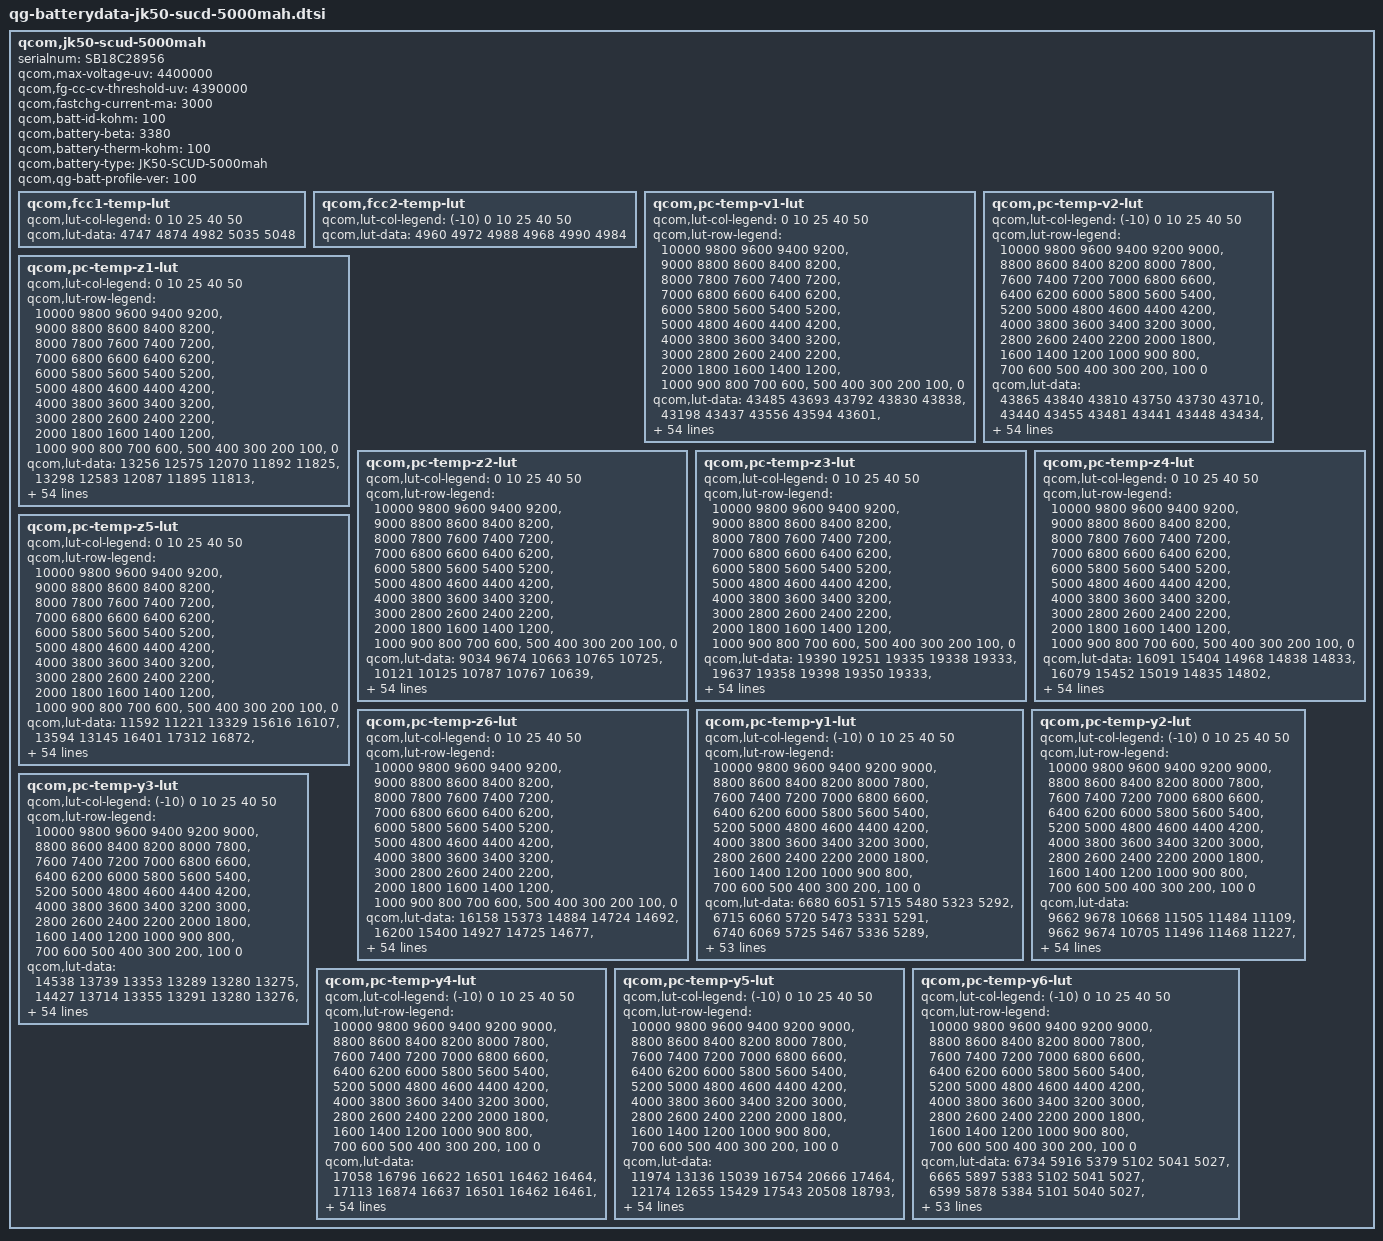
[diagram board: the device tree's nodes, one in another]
qcom,jk50-scud-5000mah {
    /* 3483956_Wingtech_JK50scud_4850mAh_averaged_MasterSlave_Jun21st2018 */
    serialnum = "SB18C28956";
    qcom,max-voltage-uv = <4400000>;
    qcom,fg-cc-cv-threshold-uv = <4390000>;
    qcom,fastchg-current-ma = <3000>;
    qcom,batt-id-kohm = <100>;
    qcom,battery-beta = <3380>;
    qcom,battery-therm-kohm = <100>;
    qcom,battery-type = "JK50-SCUD-5000mah";
    qcom,qg-batt-profile-ver = <100>;

	qcom,fcc1-temp-lut {
		qcom,lut-col-legend = <0 10 25 40 50>;
		qcom,lut-data = <4747 4874 4982 5035 5048>;
	};

	qcom,fcc2-temp-lut {
		qcom,lut-col-legend = <(-10) 0 10 25 40 50>;
		qcom,lut-data = <4960 4972 4988 4968 4990 4984>;
	};

	qcom,pc-temp-v1-lut {
		qcom,lut-col-legend = <0 10 25 40 50>;
		qcom,lut-row-legend = <10000 9800 9600 9400 9200>,
			<9000 8800 8600 8400 8200>,
			<8000 7800 7600 7400 7200>,
			<7000 6800 6600 6400 6200>,
			<6000 5800 5600 5400 5200>,
			<5000 4800 4600 4400 4200>,
			<4000 3800 3600 3400 3200>,
			<3000 2800 2600 2400 2200>,
			<2000 1800 1600 1400 1200>,
			<1000 900 800 700 600>,
			<500 400 300 200 100>,
			<0>;
		qcom,lut-data = <43485 43693 43792 43830 43838>,
			<43198 43437 43556 43594 43601>,
			<42941 43171 43314 43362 43374>,
			<42706 42915 43070 43125 43142>,
			<42480 42676 42828 42889 42908>,
			<42257 42445 42590 42654 42674>,
			<42040 42217 42355 42419 42442>,
			<41828 41995 42123 42186 42210>,
			<41619 41778 41894 41956 41976>,
			<41419 41563 41670 41727 41745>,
			<41248 41358 41446 41500 41519>,
			<41090 41181 41236 41277 41299>,
			<40890 41019 41054 41063 41083>,
			<40593 40817 40882 40860 40872>,
			<40293 40525 40664 40658 40666>,
			<40084 40244 40382 40451 40466>,
			<39918 40056 40144 40251 40274>,
			<39773 39906 39995 40074 40095>,
			<39644 39769 39870 39913 39928>,
			<39525 39647 39730 39751 39761>,
			<39404 39523 39582 39592 39598>,
			<39286 39378 39400 39419 39425>,
			<39169 39219 39126 39185 39203>,
			<39052 39041 38864 38929 38955>,
			<38938 38819 38730 38769 38788>,
			<38825 38632 38640 38668 38682>,
			<38710 38529 38558 38577 38586>,
			<38607 38453 38481 38480 38479>,
			<38518 38395 38409 38387 38378>,
			<38440 38349 38339 38305 38291>,
			<38378 38310 38275 38232 38216>,
			<38326 38271 38217 38165 38148>,
			<38286 38235 38167 38106 38090>,
			<38262 38202 38120 38051 38033>,
			<38246 38174 38076 37999 37974>,
			<38221 38142 38034 37950 37914>,
			<38181 38106 37992 37900 37855>,
			<38132 38065 37951 37851 37800>,
			<38072 38006 37897 37790 37734>,
			<37999 37917 37811 37705 37643>,
			<37909 37816 37705 37599 37532>,
			<37788 37716 37592 37486 37416>,
			<37650 37601 37464 37358 37289>,
			<37497 37444 37312 37209 37136>,
			<37348 37291 37168 37070 37000>,
			<37240 37182 37075 36978 36920>,
			<37202 37149 37044 36952 36893>,
			<37173 37121 37026 36934 36873>,
			<37145 37096 37009 36914 36852>,
			<37095 37047 36959 36849 36783>,
			<36879 36821 36723 36586 36506>,
			<36445 36388 36301 36146 36069>,
			<35877 35817 35735 35571 35498>,
			<35105 35037 34962 34786 34718>,
			<33888 33820 33779 33569 33519>,
			<30000 30000 30000 30000 30000>;
	};

	qcom,pc-temp-v2-lut {
		qcom,lut-col-legend = <(-10) 0 10 25 40 50>;
		qcom,lut-row-legend = <10000 9800 9600 9400 9200 9000>,
			<8800 8600 8400 8200 8000 7800>,
			<7600 7400 7200 7000 6800 6600>,
			<6400 6200 6000 5800 5600 5400>,
			<5200 5000 4800 4600 4400 4200>,
			<4000 3800 3600 3400 3200 3000>,
			<2800 2600 2400 2200 2000 1800>,
			<1600 1400 1200 1000 900 800>,
			<700 600 500 400 300 200>,
			<100 0>;
		qcom,lut-data = <43865 43840 43810 43750 43730 43710>,
			<43440 43455 43481 43441 43448 43434>,
			<43056 43105 43175 43154 43181 43170>,
			<42718 42793 42898 42891 42928 42920>,
			<42417 42514 42647 42650 42688 42684>,
			<42139 42253 42401 42415 42452 42450>,
			<41873 42009 42155 42180 42217 42216>,
			<41631 41775 41916 41949 41984 41983>,
			<41426 41535 41691 41722 41755 41754>,
			<41247 41293 41476 41499 41529 41528>,
			<41091 41122 41269 41281 41307 41305>,
			<40972 41031 41077 41068 41087 41086>,
			<40831 40928 40879 40860 40873 40872>,
			<40486 40636 40652 40658 40669 40665>,
			<39938 40158 40408 40458 40471 40464>,
			<39599 39838 40176 40254 40279 40271>,
			<39423 39648 39954 40039 40088 40087>,
			<39272 39474 39743 39845 39907 39909>,
			<39099 39282 39547 39699 39743 39744>,
			<38928 39091 39359 39567 39581 39579>,
			<38774 38913 39166 39384 39384 39386>,
			<38630 38743 38966 39130 39150 39158>,
			<38507 38592 38790 38900 38938 38949>,
			<38406 38457 38639 38728 38761 38770>,
			<38321 38340 38505 38583 38607 38613>,
			<38243 38251 38384 38459 38482 38485>,
			<38175 38180 38274 38353 38376 38377>,
			<38110 38117 38177 38258 38279 38278>,
			<38051 38062 38090 38173 38189 38187>,
			<37994 38012 38015 38096 38106 38104>,
			<37936 37964 37955 38022 38034 38030>,
			<37878 37918 37904 37951 37968 37962>,
			<37818 37872 37855 37886 37904 37897>,
			<37756 37824 37808 37829 37844 37836>,
			<37693 37774 37762 37775 37779 37769>,
			<37630 37721 37717 37721 37695 37673>,
			<37565 37664 37671 37668 37603 37562>,
			<37500 37601 37612 37607 37519 37466>,
			<37434 37533 37539 37537 37440 37380>,
			<37367 37455 37458 37461 37361 37296>,
			<37299 37356 37367 37379 37282 37217>,
			<37231 37255 37267 37284 37193 37130>,
			<37162 37170 37156 37169 37078 37020>,
			<37084 37093 37072 37041 36951 36891>,
			<36994 37006 36992 36929 36836 36782>,
			<36864 36886 36881 36864 36802 36746>,
			<36779 36810 36815 36848 36785 36734>,
			<36679 36723 36744 36828 36768 36717>,
			<36567 36642 36695 36792 36735 36686>,
			<36425 36579 36623 36724 36630 36573>,
			<36219 36418 36431 36480 36299 36236>,
			<35863 36015 35969 36015 35791 35737>,
			<35288 35396 35329 35393 35131 35083>,
			<34412 34531 34446 34553 34212 34177>,
			<32898 33107 33075 33275 32827 32842>,
			<30006 28192 27750 28954 27842 28553>;
	};

	qcom,pc-temp-z1-lut {
		qcom,lut-col-legend = <0 10 25 40 50>;
		qcom,lut-row-legend = <10000 9800 9600 9400 9200>,
			<9000 8800 8600 8400 8200>,
			<8000 7800 7600 7400 7200>,
			<7000 6800 6600 6400 6200>,
			<6000 5800 5600 5400 5200>,
			<5000 4800 4600 4400 4200>,
			<4000 3800 3600 3400 3200>,
			<3000 2800 2600 2400 2200>,
			<2000 1800 1600 1400 1200>,
			<1000 900 800 700 600>,
			<500 400 300 200 100>,
			<0>;
		qcom,lut-data = <13256 12575 12070 11892 11825>,
			<13298 12583 12087 11895 11813>,
			<13303 12582 12089 11892 11810>,
			<13285 12583 12079 11881 11802>,
			<13269 12584 12073 11871 11796>,
			<13266 12581 12070 11866 11791>,
			<13266 12574 12068 11863 11788>,
			<13260 12562 12065 11859 11787>,
			<13247 12558 12061 11856 11786>,
			<13241 12557 12059 11854 11786>,
			<13248 12557 12059 11855 11787>,
			<13254 12557 12062 11855 11789>,
			<13245 12556 12061 11856 11789>,
			<13200 12549 12057 11857 11789>,
			<13156 12527 12053 11857 11789>,
			<13135 12508 12048 11855 11789>,
			<13117 12504 12046 11854 11790>,
			<13111 12503 12046 11854 11791>,
			<13120 12505 12046 11856 11792>,
			<13132 12516 12048 11858 11794>,
			<13129 12527 12056 11859 11795>,
			<13111 12532 12061 11860 11797>,
			<13102 12536 12061 11862 11798>,
			<13120 12541 12062 11866 11799>,
			<13148 12546 12064 11868 11800>,
			<13157 12550 12068 11871 11804>,
			<13159 12551 12071 11874 11808>,
			<13159 12552 12074 11876 11810>,
			<13159 12552 12077 11879 11813>,
			<13161 12551 12080 11884 11816>,
			<13162 12551 12083 11890 11820>,
			<13162 12556 12085 11894 11824>,
			<13164 12564 12088 11897 11828>,
			<13171 12570 12091 11900 11832>,
			<13181 12579 12097 11906 11837>,
			<13184 12586 12103 11913 11843>,
			<13194 12593 12106 11916 11847>,
			<13204 12604 12107 11917 11851>,
			<13215 12610 12110 11918 11854>,
			<13239 12618 12121 11924 11857>,
			<13247 12625 12132 11931 11859>,
			<13254 12628 12131 11934 11864>,
			<13261 12630 12126 11937 11870>,
			<13261 12637 12133 11941 11872>,
			<13269 12639 12145 11944 11874>,
			<13238 12641 12141 11944 11877>,
			<13239 12638 12143 11945 11876>,
			<13270 12627 12144 11948 11878>,
			<13263 12648 12140 11949 11882>,
			<13252 12629 12219 11953 11884>,
			<13303 12653 12156 11964 11890>,
			<13291 12665 12160 11971 11898>,
			<13307 12695 12173 11979 11909>,
			<13344 12730 12198 11997 11922>,
			<13344 12730 12198 11997 11922>,
			<13344 12730 12198 11997 11922>;
	};

	qcom,pc-temp-z2-lut {
		qcom,lut-col-legend = <0 10 25 40 50>;
		qcom,lut-row-legend = <10000 9800 9600 9400 9200>,
			<9000 8800 8600 8400 8200>,
			<8000 7800 7600 7400 7200>,
			<7000 6800 6600 6400 6200>,
			<6000 5800 5600 5400 5200>,
			<5000 4800 4600 4400 4200>,
			<4000 3800 3600 3400 3200>,
			<3000 2800 2600 2400 2200>,
			<2000 1800 1600 1400 1200>,
			<1000 900 800 700 600>,
			<500 400 300 200 100>,
			<0>;
		qcom,lut-data = <9034 9674 10663 10765 10725>,
			<10121 10125 10787 10767 10639>,
			<10373 10493 10853 10891 10675>,
			<10398 10604 10859 10864 10766>,
			<10415 10592 10847 10827 10825>,
			<10436 10572 10820 10814 10805>,
			<10455 10555 10791 10805 10719>,
			<10461 10536 10771 10789 10675>,
			<10462 10520 10753 10740 10676>,
			<10459 10505 10738 10706 10680>,
			<10382 10497 10724 10712 10679>,
			<10143 10516 10716 10721 10676>,
			<10019 10567 10739 10719 10665>,
			<10125 10585 10786 10705 10632>,
			<10283 10567 10810 10698 10615>,
			<10366 10550 10821 10725 10645>,
			<10463 10562 10823 10757 10679>,
			<10497 10602 10815 10756 10655>,
			<10454 10644 10811 10744 10585>,
			<10415 10696 10830 10743 10560>,
			<10422 10736 10877 10794 10639>,
			<10428 10747 10896 10840 10718>,
			<10433 10754 10889 10826 10697>,
			<10437 10754 10876 10791 10642>,
			<10441 10746 10859 10769 10630>,
			<10449 10739 10836 10758 10653>,
			<10462 10751 10830 10763 10692>,
			<10477 10776 10851 10879 10813>,
			<10494 10783 10876 11031 10957>,
			<10515 10777 10892 11023 10939>,
			<10540 10773 10911 10918 10778>,
			<10573 10779 10915 10832 10644>,
			<10595 10796 10905 10770 10548>,
			<10345 10812 10898 10734 10491>,
			<9819 10830 10903 10754 10505>,
			<9652 10849 10914 10811 10547>,
			<9741 10870 10928 10866 10586>,
			<9842 10892 10951 10927 10643>,
			<9891 10918 10978 10970 10701>,
			<9936 10952 11019 10998 10786>,
			<9949 10971 11056 11021 10873>,
			<9862 10848 11068 11028 10866>,
			<9797 10671 11074 11030 10806>,
			<9816 10611 11078 11038 10874>,
			<9724 12174 11129 11035 10940>,
			<9649 14416 11230 10993 10790>,
			<9693 13140 11233 10967 10802>,
			<9703 13467 11241 10974 10813>,
			<9679 14092 11296 11005 10871>,
			<9664 14667 11387 11156 10993>,
			<9590 13142 11358 11016 10724>,
			<9567 12520 11366 10836 10551>,
			<9502 11311 11285 10745 10455>,
			<9427 11330 11100 10671 10428>,
			<9427 11330 11100 10671 10428>,
			<9427 11330 11100 10671 10428>;
	};

	qcom,pc-temp-z3-lut {
		qcom,lut-col-legend = <0 10 25 40 50>;
		qcom,lut-row-legend = <10000 9800 9600 9400 9200>,
			<9000 8800 8600 8400 8200>,
			<8000 7800 7600 7400 7200>,
			<7000 6800 6600 6400 6200>,
			<6000 5800 5600 5400 5200>,
			<5000 4800 4600 4400 4200>,
			<4000 3800 3600 3400 3200>,
			<3000 2800 2600 2400 2200>,
			<2000 1800 1600 1400 1200>,
			<1000 900 800 700 600>,
			<500 400 300 200 100>,
			<0>;
		qcom,lut-data = <19390 19251 19335 19338 19333>,
			<19637 19358 19398 19350 19333>,
			<19703 19506 19427 19372 19354>,
			<19715 19572 19438 19383 19368>,
			<19719 19577 19443 19388 19376>,
			<19712 19579 19446 19391 19378>,
			<19700 19578 19447 19393 19379>,
			<19692 19574 19446 19393 19381>,
			<19684 19572 19442 19392 19385>,
			<19677 19570 19440 19391 19388>,
			<19633 19566 19439 19389 19385>,
			<19508 19547 19437 19387 19378>,
			<19451 19509 19427 19382 19373>,
			<19571 19499 19411 19376 19369>,
			<19717 19523 19409 19372 19366>,
			<19737 19545 19424 19373 19364>,
			<19722 19539 19433 19375 19363>,
			<19702 19517 19421 19373 19359>,
			<19654 19499 19404 19365 19351>,
			<19609 19483 19400 19361 19347>,
			<19603 19473 19399 19359 19346>,
			<19602 19480 19399 19358 19345>,
			<19601 19498 19408 19357 19343>,
			<19614 19511 19417 19357 19340>,
			<19632 19520 19414 19354 19336>,
			<19641 19526 19404 19343 19332>,
			<19649 19526 19400 19337 19329>,
			<19653 19526 19400 19353 19354>,
			<19651 19525 19400 19377 19391>,
			<19646 19521 19404 19384 19395>,
			<19641 19515 19412 19388 19388>,
			<19630 19510 19416 19389 19380>,
			<19613 19504 19417 19385 19372>,
			<19513 19499 19418 19380 19363>,
			<19331 19492 19417 19374 19356>,
			<19268 19486 19415 19367 19351>,
			<19266 19482 19412 19362 19346>,
			<19265 19479 19406 19358 19341>,
			<19264 19479 19403 19356 19338>,
			<19263 19479 19401 19354 19339>,
			<19263 19477 19400 19353 19340>,
			<19264 19378 19397 19352 19341>,
			<19265 19262 19394 19351 19342>,
			<19264 19261 19391 19351 19347>,
			<19265 19259 19386 19348 19350>,
			<19267 19257 19370 19338 19334>,
			<19266 19257 19368 19332 19325>,
			<19265 19257 19360 19326 19320>,
			<19266 19257 19337 19324 19314>,
			<19266 19257 19335 19319 19309>,
			<19268 19257 19353 19329 19339>,
			<19268 19257 19341 19340 19342>,
			<19270 19259 19347 19339 19343>,
			<19273 19259 19363 19343 19341>,
			<19273 19259 19363 19343 19341>,
			<19273 19259 19363 19343 19341>;
	};

	qcom,pc-temp-z4-lut {
		qcom,lut-col-legend = <0 10 25 40 50>;
		qcom,lut-row-legend = <10000 9800 9600 9400 9200>,
			<9000 8800 8600 8400 8200>,
			<8000 7800 7600 7400 7200>,
			<7000 6800 6600 6400 6200>,
			<6000 5800 5600 5400 5200>,
			<5000 4800 4600 4400 4200>,
			<4000 3800 3600 3400 3200>,
			<3000 2800 2600 2400 2200>,
			<2000 1800 1600 1400 1200>,
			<1000 900 800 700 600>,
			<500 400 300 200 100>,
			<0>;
		qcom,lut-data = <16091 15404 14968 14838 14833>,
			<16079 15452 15019 14835 14802>,
			<15985 15351 15046 14880 14833>,
			<15782 15244 14974 14860 14826>,
			<15595 15137 14909 14827 14805>,
			<15471 15041 14864 14802 14787>,
			<15368 14973 14826 14780 14769>,
			<15285 14919 14797 14760 14752>,
			<15211 14876 14774 14744 14735>,
			<15154 14841 14755 14729 14720>,
			<15148 14817 14739 14716 14709>,
			<15210 14805 14725 14705 14702>,
			<15229 14798 14712 14697 14696>,
			<15106 14787 14701 14692 14692>,
			<14952 14766 14700 14688 14688>,
			<14896 14748 14706 14683 14684>,
			<14859 14740 14709 14678 14679>,
			<14848 14734 14697 14672 14675>,
			<14863 14730 14679 14666 14671>,
			<14878 14725 14674 14664 14670>,
			<14869 14721 14672 14666 14672>,
			<14848 14713 14675 14671 14676>,
			<14824 14704 14741 14714 14712>,
			<14793 14707 14812 14791 14786>,
			<14764 14758 14816 14808 14805>,
			<14754 14801 14810 14804 14797>,
			<14749 14799 14802 14796 14785>,
			<14747 14790 14786 14769 14747>,
			<14747 14779 14768 14732 14698>,
			<14748 14764 14750 14711 14685>,
			<14748 14748 14732 14695 14681>,
			<14746 14736 14717 14685 14677>,
			<14744 14725 14705 14678 14672>,
			<14830 14715 14695 14674 14669>,
			<15013 14707 14690 14673 14669>,
			<15074 14701 14685 14673 14670>,
			<15063 14694 14683 14673 14670>,
			<15048 14688 14681 14672 14670>,
			<15036 14686 14681 14672 14669>,
			<15024 14685 14685 14678 14675>,
			<15015 14685 14690 14686 14684>,
			<15010 14783 14689 14686 14684>,
			<15003 14899 14683 14680 14677>,
			<14984 14894 14681 14680 14675>,
			<14914 14859 14674 14678 14670>,
			<14880 14828 14657 14660 14655>,
			<14876 14821 14651 14658 14656>,
			<14872 14816 14649 14650 14648>,
			<14865 14809 14663 14636 14635>,
			<14862 14805 14661 14639 14636>,
			<14866 14814 14661 14656 14640>,
			<14885 14826 14683 14656 14649>,
			<14899 14834 14681 14661 14653>,
			<14915 14843 14669 14661 14659>,
			<14915 14843 14669 14661 14659>,
			<14915 14843 14669 14661 14659>;
	};

	qcom,pc-temp-z5-lut {
		qcom,lut-col-legend = <0 10 25 40 50>;
		qcom,lut-row-legend = <10000 9800 9600 9400 9200>,
			<9000 8800 8600 8400 8200>,
			<8000 7800 7600 7400 7200>,
			<7000 6800 6600 6400 6200>,
			<6000 5800 5600 5400 5200>,
			<5000 4800 4600 4400 4200>,
			<4000 3800 3600 3400 3200>,
			<3000 2800 2600 2400 2200>,
			<2000 1800 1600 1400 1200>,
			<1000 900 800 700 600>,
			<500 400 300 200 100>,
			<0>;
		qcom,lut-data = <11592 11221 13329 15616 16107>,
			<13594 13145 16401 17312 16872>,
			<14386 15417 17404 18541 18534>,
			<14698 16893 18322 19395 19833>,
			<14917 17574 19268 20084 20945>,
			<15146 18085 20133 20644 21530>,
			<15362 18663 20811 21187 21844>,
			<15557 19329 21309 21742 22423>,
			<15748 20037 21820 22260 24431>,
			<15905 21018 22482 22866 26263>,
			<15536 21689 23650 24032 26593>,
			<14168 20823 24411 25365 26737>,
			<13740 18611 24050 25571 26956>,
			<16828 18297 23026 25268 27315>,
			<20591 24197 24110 25157 27858>,
			<21563 29699 31048 27952 29592>,
			<21394 28707 35189 31420 31578>,
			<20723 25436 31760 31686 31482>,
			<18683 23541 27405 31430 30193>,
			<16824 22588 27599 31398 29705>,
			<16790 22116 30911 32724 31505>,
			<17375 26031 35255 34041 33332>,
			<18347 36592 42361 32981 31504>,
			<20898 44631 47955 29891 26404>,
			<24806 52511 44209 26186 22364>,
			<29065 57236 33025 20869 18762>,
			<35368 55539 27300 18211 16998>,
			<40043 51052 25306 19945 22460>,
			<41587 47076 24425 23082 30763>,
			<42366 43365 25322 25961 32866>,
			<41522 40393 27658 29156 33442>,
			<38663 38615 30110 32022 33359>,
			<34464 37264 32978 34807 32457>,
			<26268 36139 36030 36733 31650>,
			<15112 34771 39821 37314 32012>,
			<11627 33709 43021 37679 32989>,
			<11625 33915 42979 37606 33140>,
			<11624 35159 41255 36524 31942>,
			<11633 36115 40050 34970 30475>,
			<11662 38579 39139 32696 29165>,
			<11698 40240 37992 30075 27967>,
			<11757 27430 35768 28159 27300>,
			<11813 12139 32740 26718 26836>,
			<11855 12099 32292 26532 29541>,
			<12244 12283 32656 26209 32053>,
			<12386 12382 30401 24859 24994>,
			<12358 12284 30268 22733 21105>,
			<12339 12270 27048 21691 21051>,
			<12364 12268 19592 23347 21714>,
			<12348 12301 19553 21268 19855>,
			<12461 12354 22713 20147 27204>,
			<12326 12232 18793 20761 23710>,
			<12198 12152 18647 19387 21460>,
			<12044 12020 20356 18837 18803>,
			<12044 12020 20356 18837 18803>,
			<12044 12020 20356 18837 18803>;
	};

	qcom,pc-temp-z6-lut {
		qcom,lut-col-legend = <0 10 25 40 50>;
		qcom,lut-row-legend = <10000 9800 9600 9400 9200>,
			<9000 8800 8600 8400 8200>,
			<8000 7800 7600 7400 7200>,
			<7000 6800 6600 6400 6200>,
			<6000 5800 5600 5400 5200>,
			<5000 4800 4600 4400 4200>,
			<4000 3800 3600 3400 3200>,
			<3000 2800 2600 2400 2200>,
			<2000 1800 1600 1400 1200>,
			<1000 900 800 700 600>,
			<500 400 300 200 100>,
			<0>;
		qcom,lut-data = <16158 15373 14884 14724 14692>,
			<16200 15400 14927 14725 14677>,
			<16179 15390 14943 14752 14700>,
			<16050 15372 14910 14746 14701>,
			<15912 15309 14878 14733 14697>,
			<15821 15235 14853 14723 14691>,
			<15744 15186 14832 14712 14683>,
			<15680 15147 14813 14703 14676>,
			<15629 15115 14798 14694 14671>,
			<15582 15091 14786 14687 14666>,
			<15533 15068 14777 14680 14660>,
			<15483 15039 14768 14673 14653>,
			<15451 15009 14755 14667 14648>,
			<15434 14991 14740 14661 14644>,
			<15418 14983 14738 14657 14640>,
			<15396 14976 14745 14655 14637>,
			<15367 14966 14749 14653 14634>,
			<15341 14955 14739 14649 14630>,
			<15320 14945 14724 14643 14624>,
			<15302 14938 14721 14640 14622>,
			<15288 14933 14721 14641 14623>,
			<15277 14935 14724 14642 14624>,
			<15270 14943 14757 14660 14638>,
			<15266 14954 14793 14693 14668>,
			<15264 14983 14795 14700 14676>,
			<15264 15005 14789 14694 14670>,
			<15271 15005 14784 14688 14665>,
			<15276 15003 14778 14685 14663>,
			<15278 15000 14773 14683 14662>,
			<15278 14993 14769 14680 14659>,
			<15277 14986 14766 14676 14654>,
			<15272 14979 14764 14672 14649>,
			<15266 14974 14761 14668 14643>,
			<15257 14969 14759 14665 14638>,
			<15248 14965 14757 14662 14635>,
			<15244 14962 14756 14660 14633>,
			<15243 14962 14755 14658 14631>,
			<15243 14962 14754 14656 14628>,
			<15243 14962 14753 14655 14627>,
			<15244 14967 14757 14658 14631>,
			<15246 14970 14761 14662 14636>,
			<15252 14968 14761 14662 14636>,
			<15256 14965 14760 14661 14635>,
			<15256 14968 14761 14661 14637>,
			<15241 14963 14759 14660 14638>,
			<15229 14953 14747 14648 14624>,
			<15228 14951 14743 14645 14620>,
			<15226 14950 14739 14638 14613>,
			<15223 14949 14735 14632 14604>,
			<15228 14951 14736 14632 14603>,
			<15239 14960 14748 14646 14622>,
			<15254 14971 14756 14654 14631>,
			<15273 14985 14763 14660 14636>,
			<15301 15004 14773 14666 14641>,
			<15301 15004 14773 14666 14641>,
			<15301 15004 14773 14666 14641>;
	};

	qcom,pc-temp-y1-lut {
		qcom,lut-col-legend = <(-10) 0 10 25 40 50>;
		qcom,lut-row-legend = <10000 9800 9600 9400 9200 9000>,
			<8800 8600 8400 8200 8000 7800>,
			<7600 7400 7200 7000 6800 6600>,
			<6400 6200 6000 5800 5600 5400>,
			<5200 5000 4800 4600 4400 4200>,
			<4000 3800 3600 3400 3200 3000>,
			<2800 2600 2400 2200 2000 1800>,
			<1600 1400 1200 1000 900 800>,
			<700 600 500 400 300 200>,
			<100 0>;
		qcom,lut-data = <6680 6051 5715 5480 5323 5292>,
			<6715 6060 5720 5473 5331 5291>,
			<6740 6069 5725 5467 5336 5289>,
			<6755 6078 5730 5462 5339 5288>,
			<6762 6083 5734 5459 5340 5287>,
			<6764 6085 5736 5457 5340 5286>,
			<6752 6079 5737 5457 5337 5285>,
			<6740 6071 5737 5458 5334 5284>,
			<6740 6068 5733 5458 5332 5282>,
			<6747 6066 5728 5456 5331 5280>,
			<6749 6068 5727 5455 5330 5279>,
			<6756 6075 5729 5455 5328 5278>,
			<6764 6084 5732 5455 5326 5277>,
			<6759 6089 5734 5455 5325 5277>,
			<6747 6093 5739 5454 5323 5277>,
			<6744 6097 5740 5455 5323 5277>,
			<6752 6103 5740 5460 5325 5276>,
			<6761 6107 5740 5464 5327 5276>,
			<6767 6101 5741 5464 5328 5277>,
			<6771 6090 5745 5464 5328 5278>,
			<6766 6088 5747 5464 5329 5279>,
			<6748 6089 5748 5463 5329 5279>,
			<6734 6092 5749 5463 5329 5279>,
			<6736 6103 5750 5466 5332 5281>,
			<6743 6116 5751 5469 5335 5283>,
			<6739 6116 5751 5469 5337 5285>,
			<6724 6109 5749 5470 5339 5287>,
			<6715 6103 5748 5470 5340 5289>,
			<6726 6099 5749 5475 5342 5290>,
			<6742 6097 5749 5482 5343 5291>,
			<6740 6099 5747 5484 5346 5293>,
			<6728 6103 5744 5485 5348 5297>,
			<6723 6104 5744 5485 5350 5301>,
			<6724 6099 5748 5485 5351 5304>,
			<6726 6092 5752 5486 5352 5306>,
			<6730 6091 5750 5486 5356 5308>,
			<6737 6094 5747 5487 5361 5309>,
			<6743 6096 5748 5487 5362 5311>,
			<6749 6098 5753 5486 5363 5314>,
			<6751 6098 5755 5486 5364 5316>,
			<6735 6099 5752 5487 5366 5317>,
			<6722 6096 5750 5490 5367 5317>,
			<6742 6100 5756 5491 5371 5320>,
			<6732 6112 5754 5490 5374 5322>,
			<6779 6116 5763 5494 5377 5326>,
			<6778 6122 5769 5493 5381 5330>,
			<6791 6139 5762 5502 5380 5331>,
			<6772 6145 5767 5496 5381 5328>,
			<6768 6130 5762 5498 5377 5328>,
			<6793 6146 5768 5504 5377 5331>,
			<6797 6155 5777 5506 5381 5332>,
			<6806 6155 5782 5515 5391 5337>,
			<6831 6195 5801 5524 5399 5345>,
			<6887 6221 5824 5538 5408 5353>,
			<6887 6221 5824 5538 5408 5353>,
			<6887 6221 5824 5538 5408 5353>;
	};

	qcom,pc-temp-y2-lut {
		qcom,lut-col-legend = <(-10) 0 10 25 40 50>;
		qcom,lut-row-legend = <10000 9800 9600 9400 9200 9000>,
			<8800 8600 8400 8200 8000 7800>,
			<7600 7400 7200 7000 6800 6600>,
			<6400 6200 6000 5800 5600 5400>,
			<5200 5000 4800 4600 4400 4200>,
			<4000 3800 3600 3400 3200 3000>,
			<2800 2600 2400 2200 2000 1800>,
			<1600 1400 1200 1000 900 800>,
			<700 600 500 400 300 200>,
			<100 0>;
		qcom,lut-data = <9662 9678 10668 11505 11484 11109>,
			<9662 9674 10705 11496 11468 11227>,
			<9663 9674 10752 11483 11447 11302>,
			<9663 9676 10799 11467 11424 11341>,
			<9664 9679 10834 11448 11401 11351>,
			<9664 9684 10846 11427 11379 11338>,
			<9665 9693 10843 11403 11331 11276>,
			<9665 9700 10837 11377 11284 11208>,
			<9665 9700 10828 11350 11289 11197>,
			<9665 9697 10817 11320 11328 11199>,
			<9665 9695 10818 11295 11338 11191>,
			<9665 9699 10884 11272 11320 11139>,
			<9666 9703 10974 11259 11301 11094>,
			<9665 9701 11050 11265 11290 11093>,
			<9665 9694 11126 11290 11283 11095>,
			<9664 9689 11180 11325 11294 11112>,
			<9664 9686 11227 11393 11342 11217>,
			<9664 9683 11253 11471 11405 11317>,
			<9664 9681 11258 11561 11491 11360>,
			<9664 9680 11261 11648 11580 11393>,
			<9664 9680 11269 11656 11613 11411>,
			<9664 9679 11290 11610 11626 11402>,
			<9664 9678 11309 11582 11626 11391>,
			<9664 9678 11324 11631 11604 11381>,
			<9664 9677 11339 11700 11584 11381>,
			<9663 9676 11354 11715 11603 11406>,
			<9663 9674 11369 11716 11656 11442>,
			<9663 9673 11326 11719 11695 11481>,
			<9663 9671 10675 11735 11746 11531>,
			<9663 9670 10071 11754 11793 11568>,
			<9663 9669 10228 11762 11813 11580>,
			<9662 9668 10561 11759 11826 11587>,
			<9662 9666 10544 11753 11832 11609>,
			<9662 9665 10126 11752 11839 11687>,
			<9662 9664 9847 11753 11840 11741>,
			<9662 9664 9799 11741 11827 11698>,
			<9662 9663 9766 11713 11801 11631>,
			<9662 9662 9742 11681 11758 11619>,
			<9662 9662 9723 11649 11681 11596>,
			<9661 9661 9711 11611 11635 11568>,
			<9661 9661 9703 11557 11645 11535>,
			<9661 9661 9696 11504 11641 11508>,
			<9660 9660 9689 11465 11561 11472>,
			<9660 9660 9682 11410 11630 11424>,
			<9660 9660 9681 11385 11567 11362>,
			<9660 9659 9675 10943 11475 11238>,
			<9660 9659 9673 11230 11424 11199>,
			<9659 9659 9673 11233 11444 11209>,
			<9659 9659 9674 11207 11431 11280>,
			<9659 9659 9676 11227 11439 11293>,
			<9658 9659 9677 11168 11333 11148>,
			<9658 9658 9672 11012 11275 11064>,
			<9657 9658 9664 10895 11174 11004>,
			<9655 9657 9660 10739 11005 10825>,
			<9655 9657 9660 10739 11005 10825>,
			<9655 9657 9660 10739 11005 10825>;
	};

	qcom,pc-temp-y3-lut {
		qcom,lut-col-legend = <(-10) 0 10 25 40 50>;
		qcom,lut-row-legend = <10000 9800 9600 9400 9200 9000>,
			<8800 8600 8400 8200 8000 7800>,
			<7600 7400 7200 7000 6800 6600>,
			<6400 6200 6000 5800 5600 5400>,
			<5200 5000 4800 4600 4400 4200>,
			<4000 3800 3600 3400 3200 3000>,
			<2800 2600 2400 2200 2000 1800>,
			<1600 1400 1200 1000 900 800>,
			<700 600 500 400 300 200>,
			<100 0>;
		qcom,lut-data = <14538 13739 13353 13289 13280 13275>,
			<14427 13714 13355 13291 13280 13276>,
			<14319 13683 13358 13292 13280 13277>,
			<14220 13652 13362 13294 13280 13277>,
			<14133 13627 13365 13295 13280 13278>,
			<14065 13613 13366 13296 13280 13279>,
			<14017 13609 13367 13296 13281 13279>,
			<13973 13605 13368 13297 13281 13280>,
			<13895 13582 13371 13297 13281 13280>,
			<13789 13527 13376 13298 13283 13281>,
			<13752 13502 13378 13298 13283 13281>,
			<13768 13498 13377 13299 13283 13281>,
			<13785 13495 13375 13300 13283 13281>,
			<13766 13490 13368 13303 13285 13281>,
			<13718 13484 13355 13307 13288 13282>,
			<13697 13477 13350 13308 13289 13283>,
			<13690 13463 13349 13305 13289 13285>,
			<13688 13447 13348 13302 13289 13287>,
			<13689 13429 13344 13303 13290 13287>,
			<13693 13413 13338 13304 13290 13288>,
			<13694 13407 13332 13304 13290 13287>,
			<13696 13405 13327 13299 13286 13283>,
			<13698 13405 13323 13294 13283 13280>,
			<13705 13404 13320 13290 13281 13278>,
			<13718 13404 13318 13288 13279 13277>,
			<13730 13407 13316 13287 13279 13277>,
			<13743 13417 13313 13286 13279 13277>,
			<13759 13429 13307 13286 13279 13277>,
			<13782 13443 13283 13288 13278 13277>,
			<13809 13462 13264 13290 13278 13276>,
			<13838 13484 13271 13290 13278 13276>,
			<13868 13511 13285 13289 13278 13276>,
			<13899 13539 13289 13289 13279 13276>,
			<13930 13567 13297 13289 13280 13277>,
			<13962 13599 13305 13290 13280 13278>,
			<13998 13636 13313 13290 13279 13277>,
			<14037 13676 13320 13290 13278 13275>,
			<14078 13721 13322 13290 13278 13275>,
			<14121 13770 13323 13291 13278 13276>,
			<14164 13821 13324 13291 13278 13276>,
			<14209 13869 13334 13291 13279 13277>,
			<14256 13920 13348 13292 13279 13278>,
			<14316 13979 13359 13293 13279 13279>,
			<14369 14049 13386 13293 13279 13277>,
			<14318 14021 13389 13292 13275 13274>,
			<14415 14111 13433 13292 13283 13280>,
			<14464 14158 13458 13299 13284 13283>,
			<14523 14189 13475 13306 13289 13286>,
			<14580 14214 13501 13312 13293 13289>,
			<14640 14226 13501 13317 13292 13287>,
			<14713 14219 13503 13312 13287 13283>,
			<14812 14267 13524 13311 13287 13284>,
			<14961 14442 13650 13319 13293 13287>,
			<15480 14661 13861 13334 13299 13294>,
			<15480 14661 13861 13334 13299 13294>,
			<15480 14661 13861 13334 13299 13294>;
	};

	qcom,pc-temp-y4-lut {
		qcom,lut-col-legend = <(-10) 0 10 25 40 50>;
		qcom,lut-row-legend = <10000 9800 9600 9400 9200 9000>,
			<8800 8600 8400 8200 8000 7800>,
			<7600 7400 7200 7000 6800 6600>,
			<6400 6200 6000 5800 5600 5400>,
			<5200 5000 4800 4600 4400 4200>,
			<4000 3800 3600 3400 3200 3000>,
			<2800 2600 2400 2200 2000 1800>,
			<1600 1400 1200 1000 900 800>,
			<700 600 500 400 300 200>,
			<100 0>;
		qcom,lut-data = <17058 16796 16622 16501 16462 16464>,
			<17113 16874 16637 16501 16462 16461>,
			<17163 16942 16660 16501 16462 16459>,
			<17204 16995 16683 16501 16462 16458>,
			<17231 17029 16701 16501 16462 16457>,
			<17240 17038 16706 16502 16463 16457>,
			<17225 17017 16704 16503 16464 16458>,
			<17208 16991 16701 16505 16466 16459>,
			<17271 17014 16701 16507 16468 16460>,
			<17474 17107 16701 16512 16469 16461>,
			<17558 17209 16705 16516 16471 16463>,
			<17544 17341 16744 16520 16476 16466>,
			<17514 17433 16791 16526 16481 16470>,
			<17349 17293 16820 16536 16485 16474>,
			<17018 16970 16843 16553 16490 16479>,
			<16909 16868 16841 16568 16496 16484>,
			<16904 16863 16793 16580 16505 16488>,
			<16898 16857 16744 16595 16516 16495>,
			<16870 16839 16720 16625 16540 16513>,
			<16822 16808 16700 16659 16566 16535>,
			<16792 16772 16666 16652 16563 16535>,
			<16771 16723 16613 16577 16532 16517>,
			<16761 16685 16575 16515 16502 16497>,
			<16760 16658 16556 16492 16477 16476>,
			<16759 16641 16543 16479 16459 16458>,
			<16759 16639 16534 16477 16457 16456>,
			<16760 16641 16527 16478 16457 16456>,
			<16761 16643 16528 16479 16459 16456>,
			<16761 16643 16567 16482 16464 16460>,
			<16762 16645 16604 16484 16471 16467>,
			<16763 16647 16591 16487 16479 16474>,
			<16766 16651 16565 16491 16487 16483>,
			<16770 16656 16562 16492 16495 16492>,
			<16776 16664 16572 16493 16501 16501>,
			<16783 16672 16581 16493 16504 16506>,
			<16787 16679 16589 16493 16491 16493>,
			<16790 16686 16600 16492 16470 16470>,
			<16795 16691 16612 16490 16463 16462>,
			<16803 16697 16623 16488 16460 16459>,
			<16814 16699 16631 16486 16460 16458>,
			<16832 16694 16637 16491 16466 16465>,
			<16856 16689 16638 16499 16472 16471>,
			<16881 16692 16633 16501 16474 16471>,
			<16899 16697 16634 16499 16463 16460>,
			<16845 16692 16632 16486 16453 16446>,
			<16866 16726 16665 16509 16462 16460>,
			<16884 16762 16702 16519 16481 16486>,
			<16909 16794 16768 16544 16510 16522>,
			<16939 16862 16858 16584 16549 16556>,
			<16975 16966 16935 16642 16556 16548>,
			<17016 17003 16931 16602 16493 16481>,
			<17026 16938 16855 16552 16479 16472>,
			<17037 16903 16877 16562 16488 16475>,
			<17271 16909 16943 16597 16519 16494>,
			<17271 16909 16943 16597 16519 16494>,
			<17271 16909 16943 16597 16519 16494>;
	};

	qcom,pc-temp-y5-lut {
		qcom,lut-col-legend = <(-10) 0 10 25 40 50>;
		qcom,lut-row-legend = <10000 9800 9600 9400 9200 9000>,
			<8800 8600 8400 8200 8000 7800>,
			<7600 7400 7200 7000 6800 6600>,
			<6400 6200 6000 5800 5600 5400>,
			<5200 5000 4800 4600 4400 4200>,
			<4000 3800 3600 3400 3200 3000>,
			<2800 2600 2400 2200 2000 1800>,
			<1600 1400 1200 1000 900 800>,
			<700 600 500 400 300 200>,
			<100 0>;
		qcom,lut-data = <11974 13136 15039 16754 20666 17464>,
			<12174 12655 15429 17543 20508 18793>,
			<12377 12489 16183 18014 20176 19727>,
			<12585 12562 17030 18250 19734 20321>,
			<12795 12801 17702 18332 19239 20623>,
			<13009 13137 17934 18338 18746 20680>,
			<13285 13880 17909 18121 18062 20165>,
			<13498 14567 17879 17726 17472 19431>,
			<13374 14086 18332 17286 17365 19059>,
			<12938 12462 19614 16732 17356 18804>,
			<12981 11964 19884 16343 17164 18414>,
			<17181 14305 17253 15968 16508 17630>,
			<21379 16645 14897 15734 15960 16862>,
			<19511 16786 15575 15949 16155 16376>,
			<14505 16489 17431 16368 16652 16000>,
			<12944 16131 18906 16393 16598 15966>,
			<13263 15379 20162 15769 15954 16287>,
			<13579 14731 21065 15302 15561 16513>,
			<13729 14424 21583 16201 15664 16325>,
			<13857 14221 21949 18274 15947 16031>,
			<13784 14191 22115 20105 16969 16511>,
			<13205 14191 22074 22007 19875 18882>,
			<12691 14185 21931 22856 21457 20457>,
			<12473 13719 21508 21590 21509 20982>,
			<12334 13048 20951 19753 21436 21309>,
			<12303 12790 20498 19025 21376 21239>,
			<12292 12604 19872 18538 21002 20833>,
			<12291 12530 18703 18538 20465 20344>,
			<12432 12611 15136 20159 19308 19170>,
			<12634 12755 12285 22066 18471 18169>,
			<12727 12907 13039 22277 18597 17993>,
			<12785 13102 14593 21908 19044 17903>,
			<12777 13238 14708 21726 19765 18094>,
			<12701 13324 13784 22078 21296 19632>,
			<12626 13404 13397 22499 22257 20759>,
			<12625 13492 13778 22575 22271 20784>,
			<12686 13588 14166 22576 22214 20795>,
			<12727 13748 14147 22467 22008 20839>,
			<12792 14042 13814 21903 21420 20941>,
			<12835 14199 13642 21119 20810 20966>,
			<12774 13853 13888 20029 20209 20649>,
			<12770 13382 14037 19136 19661 20529>,
			<12970 13304 13649 18922 19227 21405>,
			<13165 13487 13777 18485 20077 20420>,
			<13435 13332 13534 18829 16830 17628>,
			<13636 13429 13617 16400 18882 18405>,
			<13759 13656 14143 17626 17896 17981>,
			<14136 14761 14791 18305 18406 17233>,
			<14945 16254 16478 18454 18356 17112>,
			<15965 17898 17081 19239 18270 16959>,
			<16566 17780 16636 18104 18317 17457>,
			<16146 15976 14717 18395 19101 18014>,
			<14513 14102 13439 18134 20725 18238>,
			<12328 13096 12721 18974 23117 22312>,
			<12328 13096 12721 18974 23117 22312>,
			<12328 13096 12721 18974 23117 22312>;
	};

	qcom,pc-temp-y6-lut {
		qcom,lut-col-legend = <(-10) 0 10 25 40 50>;
		qcom,lut-row-legend = <10000 9800 9600 9400 9200 9000>,
			<8800 8600 8400 8200 8000 7800>,
			<7600 7400 7200 7000 6800 6600>,
			<6400 6200 6000 5800 5600 5400>,
			<5200 5000 4800 4600 4400 4200>,
			<4000 3800 3600 3400 3200 3000>,
			<2800 2600 2400 2200 2000 1800>,
			<1600 1400 1200 1000 900 800>,
			<700 600 500 400 300 200>,
			<100 0>;
		qcom,lut-data = <6734 5916 5379 5102 5041 5027>,
			<6665 5897 5383 5102 5041 5027>,
			<6599 5878 5384 5101 5040 5027>,
			<6538 5860 5382 5101 5039 5027>,
			<6481 5844 5378 5101 5039 5028>,
			<6430 5828 5374 5100 5039 5028>,
			<6380 5814 5366 5099 5039 5028>,
			<6339 5800 5358 5099 5040 5029>,
			<6314 5786 5354 5099 5040 5029>,
			<6296 5771 5351 5099 5041 5030>,
			<6288 5768 5351 5100 5042 5031>,
			<6290 5798 5356 5101 5043 5031>,
			<6292 5826 5361 5102 5044 5033>,
			<6239 5788 5360 5106 5047 5034>,
			<6117 5697 5356 5114 5050 5035>,
			<6072 5660 5350 5118 5053 5037>,
			<6067 5653 5338 5120 5055 5040>,
			<6063 5646 5325 5123 5058 5044>,
			<6054 5634 5314 5131 5065 5050>,
			<6045 5621 5303 5141 5073 5055>,
			<6040 5609 5289 5139 5071 5055>,
			<6037 5598 5269 5114 5060 5047>,
			<6035 5593 5257 5093 5049 5039>,
			<6040 5593 5250 5085 5040 5031>,
			<6051 5593 5246 5080 5034 5025>,
			<6060 5597 5246 5079 5034 5025>,
			<6068 5611 5246 5080 5034 5025>,
			<6079 5627 5246 5081 5035 5025>,
			<6095 5644 5247 5084 5036 5026>,
			<6115 5662 5249 5088 5038 5028>,
			<6136 5684 5254 5090 5041 5030>,
			<6159 5709 5262 5091 5044 5033>,
			<6183 5736 5272 5093 5047 5036>,
			<6207 5764 5282 5094 5050 5040>,
			<6234 5793 5294 5096 5051 5042>,
			<6262 5825 5309 5098 5047 5037>,
			<6293 5859 5327 5099 5041 5030>,
			<6326 5896 5346 5100 5040 5028>,
			<6361 5936 5366 5101 5039 5028>,
			<6399 5976 5387 5103 5039 5028>,
			<6437 6013 5411 5107 5042 5031>,
			<6480 6051 5436 5112 5045 5034>,
			<6532 6097 5460 5116 5045 5035>,
			<6580 6151 5501 5119 5043 5030>,
			<6541 6132 5502 5118 5038 5025>,
			<6622 6208 5565 5128 5048 5035>,
			<6667 6254 5600 5140 5055 5044>,
			<6717 6291 5631 5154 5066 5056>,
			<6775 6330 5664 5171 5080 5068>,
			<6837 6372 5677 5192 5081 5065>,
			<6910 6379 5677 5176 5060 5043>,
			<6994 6401 5691 5168 5058 5042>,
			<7121 6526 5834 5189 5066 5046>,
			<7621 6702 6033 5227 5082 5059>,
			<7621 6702 6033 5227 5082 5059>,
			<7621 6702 6033 5227 5082 5059>;
	};

};
